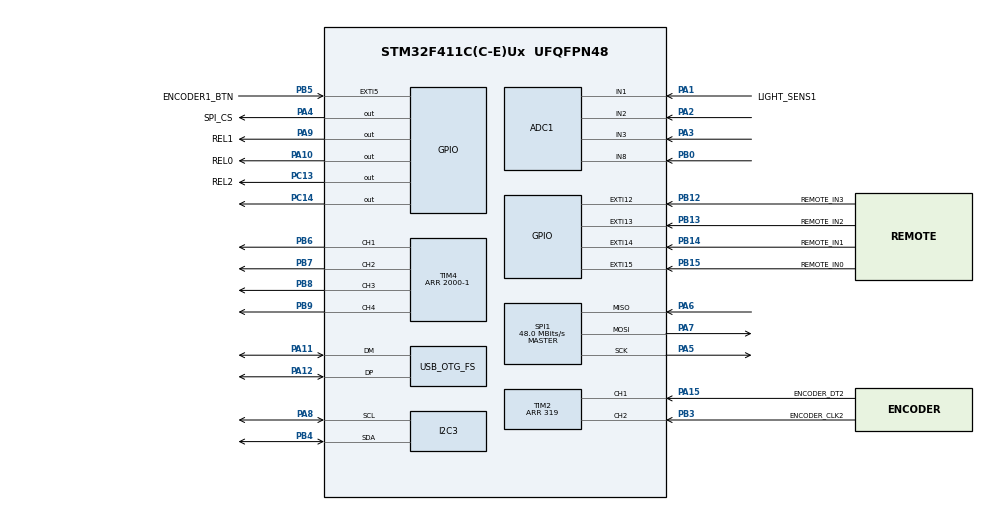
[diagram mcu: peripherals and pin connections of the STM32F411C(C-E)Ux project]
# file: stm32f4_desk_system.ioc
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ADC1.Channel-0\#ChannelRegularConversion=ADC_CHANNEL_1
ADC1.Channel-4\#ChannelRegularConversion=ADC_CHANNEL_2
ADC1.Channel-5\#ChannelRegularConversion=ADC_CHANNEL_3
ADC1.Channel-6\#ChannelRegularConversion=ADC_CHANNEL_8
ADC1.ClockPrescaler=ADC_CLOCK_SYNC_PCLK_DIV4
ADC1.ContinuousConvMode=ENABLE
ADC1.DMAContinuousRequests=ENABLE
ADC1.EOCSelection=ADC_EOC_SEQ_CONV
ADC1.NbrOfConversion=4
ADC1.NbrOfConversionFlag=1
ADC1.Rank-0\#ChannelRegularConversion=1
ADC1.Rank-4\#ChannelRegularConversion=2
ADC1.Rank-5\#ChannelRegularConversion=3
ADC1.Rank-6\#ChannelRegularConversion=4
ADC1.SamplingTime-0\#ChannelRegularConversion=ADC_SAMPLETIME_28CYCLES
ADC1.SamplingTime-4\#ChannelRegularConversion=ADC_SAMPLETIME_28CYCLES
ADC1.SamplingTime-5\#ChannelRegularConversion=ADC_SAMPLETIME_28CYCLES
ADC1.SamplingTime-6\#ChannelRegularConversion=ADC_SAMPLETIME_28CYCLES
ADC1.master=1
Dma.ADC1.0.Direction=DMA_PERIPH_TO_MEMORY
Dma.ADC1.0.FIFOMode=DMA_FIFOMODE_DISABLE
Dma.ADC1.0.Instance=DMA2_Stream0
Dma.ADC1.0.MemDataAlignment=DMA_MDATAALIGN_HALFWORD
Dma.ADC1.0.MemInc=DMA_MINC_ENABLE
Dma.ADC1.0.Mode=DMA_CIRCULAR
Dma.ADC1.0.PeriphDataAlignment=DMA_PDATAALIGN_HALFWORD
Dma.ADC1.0.PeriphInc=DMA_PINC_DISABLE
Dma.ADC1.0.Priority=DMA_PRIORITY_MEDIUM
Dma.Request0=ADC1
Mcu.Family=STM32F4
Mcu.Name=STM32F411C(C-E)Ux
Mcu.Package=UFQFPN48
NVIC.ADC_IRQn=true\:0\:0\:false\:false\:true\:true\:true
NVIC.DMA2_Stream0_IRQn=true\:0\:0\:false\:false\:true\:false\:true
NVIC.EXTI15_10_IRQn=true\:0\:0\:false\:false\:true\:true\:true
NVIC.EXTI9_5_IRQn=true\:0\:0\:false\:false\:true\:true\:true
NVIC.OTG_FS_IRQn=true\:0\:0\:false\:false\:true\:false\:true
NVIC.PriorityGroup=NVIC_PRIORITYGROUP_4
NVIC.TIM4_IRQn=true\:0\:0\:false\:false\:true\:true\:true
PA1.GPIO_Label=LIGHT_SENS1
PA1.Signal=ADCx_IN1
PA10.GPIO_Label=REL0
PA10.Signal=GPIO_Output
PA11.Mode=Device_Only
PA11.Signal=USB_OTG_FS_DM
PA12.Mode=Device_Only
PA12.Signal=USB_OTG_FS_DP
PA13.Mode=Serial_Wire
PA13.Signal=SYS_JTMS-SWDIO
PA14.Mode=Serial_Wire
PA14.Signal=SYS_JTCK-SWCLK
PA15.GPIO_Label=ENCODER_DT2
PA15.Signal=S_TIM2_CH1_ETR
PA2.Signal=ADCx_IN2
PA3.Signal=ADCx_IN3
PA4.GPIO_Label=SPI_CS
PA4.Signal=GPIO_Output
PA5.Mode=Full_Duplex_Master
PA5.Signal=SPI1_SCK
PA6.Mode=Full_Duplex_Master
PA6.Signal=SPI1_MISO
PA7.Mode=Full_Duplex_Master
PA7.Signal=SPI1_MOSI
PA8.Mode=I2C
PA8.Signal=I2C3_SCL
PA9.GPIO_Label=REL1
PA9.Signal=GPIO_Output
PB0.Signal=ADCx_IN8
PB12.GPIO_Label=REMOTE_IN3
PB12.GPIO_PuPd=GPIO_PULLDOWN
PB12.Signal=GPXTI12
PB13.GPIO_Label=REMOTE_IN2
PB13.GPIO_PuPd=GPIO_PULLDOWN
PB13.Signal=GPXTI13
PB14.GPIO_Label=REMOTE_IN1
PB14.GPIO_PuPd=GPIO_PULLDOWN
PB14.Signal=GPXTI14
PB15.GPIO_Label=REMOTE_IN0
PB15.GPIO_PuPd=GPIO_PULLDOWN
PB15.Signal=GPXTI15
PB3.GPIO_Label=ENCODER_CLK2
PB3.Signal=S_TIM2_CH2
PB4.Mode=I2C
PB4.Signal=I2C3_SDA
PB5.GPIO_Label=ENCODER1_BTN
PB5.GPIO_ModeDefaultEXTI=GPIO_MODE_IT_FALLING
PB5.Signal=GPXTI5
PB6.Signal=S_TIM4_CH1
PB7.Signal=S_TIM4_CH2
PB8.Signal=S_TIM4_CH3
PB9.Signal=S_TIM4_CH4
PC13-ANTI_TAMP.GPIO_Label=REL2
PC13-ANTI_TAMP.Signal=GPIO_Output
PC14-OSC32_IN.Signal=GPIO_Output
PH0\ -\ OSC_IN.Mode=HSE-External-Oscillator
PH0\ -\ OSC_IN.Signal=RCC_OSC_IN
PH1\ -\ OSC_OUT.Mode=HSE-External-Oscillator
PH1\ -\ OSC_OUT.Signal=RCC_OSC_OUT
ProjectManager.HeapSize=0x200
ProjectManager.StackSize=0x400
ProjectManager.TargetToolchain=STM32CubeIDE
RCC.48MHZClocksFreq_Value=48000000
RCC.AHBFreq_Value=96000000
RCC.APB1CLKDivider=RCC_HCLK_DIV2
RCC.APB1Freq_Value=48000000
RCC.APB1TimFreq_Value=96000000
RCC.APB2Freq_Value=96000000
RCC.APB2TimFreq_Value=96000000
RCC.CortexFreq_Value=96000000
RCC.HCLKFreq_Value=96000000
RCC.HSE_VALUE=25000000
RCC.HSI_VALUE=16000000
RCC.LSE_VALUE=32768
RCC.PLLM=25
RCC.SYSCLKFreq_VALUE=96000000
RCC.SYSCLKSource=RCC_SYSCLKSOURCE_PLLCLK
RCC.VCOOutputFreq_Value=192000000
SH.ADCx_IN1.0=ADC1_IN1,IN1
SH.ADCx_IN2.0=ADC1_IN2,IN2
SH.ADCx_IN3.0=ADC1_IN3,IN3
SH.ADCx_IN8.0=ADC1_IN8,IN8
SH.S_TIM2_CH1_ETR.0=TIM2_CH1,Encoder_Interface
SH.S_TIM2_CH2.0=TIM2_CH2,Encoder_Interface
SH.S_TIM4_CH1.0=TIM4_CH1,PWM Generation1 CH1
SH.S_TIM4_CH2.0=TIM4_CH2,PWM Generation2 CH2
SH.S_TIM4_CH3.0=TIM4_CH3,PWM Generation3 CH3
SH.S_TIM4_CH4.0=TIM4_CH4,PWM Generation4 CH4
SPI1.CalculateBaudRate=48.0 MBits/s
SPI1.Direction=SPI_DIRECTION_2LINES
SPI1.Mode=SPI_MODE_MASTER
SPI1.VirtualType=VM_MASTER
TIM2.CounterMode=TIM_COUNTERMODE_DOWN
TIM2.IC1Polarity=TIM_ICPOLARITY_FALLING
TIM2.IC2Polarity=TIM_ICPOLARITY_FALLING
TIM2.Period=319
TIM4.Channel-PWM\ Generation1\ CH1=TIM_CHANNEL_1
TIM4.Channel-PWM\ Generation2\ CH2=TIM_CHANNEL_2
TIM4.Channel-PWM\ Generation3\ CH3=TIM_CHANNEL_3
TIM4.Channel-PWM\ Generation4\ CH4=TIM_CHANNEL_4
TIM4.Period=2000-1
TIM9.Channel-Output\ Compare1\ No\ Output=TIM_CHANNEL_1
TIM9.Period=10000-1
TIM9.Prescaler=9
USB_DEVICE.CLASS_NAME_FS=CDC
USB_DEVICE.PRODUCT_STRING_CDC_FS=USB DESK SYSTEM
USB_DEVICE.VirtualMode=Cdc
USB_DEVICE.VirtualModeFS=Cdc_FS
USB_OTG_FS.VirtualMode=Device_Only
VP_TIM4_VS_ClockSourceINT.Mode=Internal
VP_TIM9_VS_ClockSourceINT.Mode=Internal
VP_TIM9_VS_no_output1.Mode=Output Compare1 No Output
VP_USB_DEVICE_VS_USB_DEVICE_CDC_FS.Mode=CDC_FS
board=custom

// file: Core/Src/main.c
/* USER CODE BEGIN Header */
/**
  ******************************************************************************
  * @file           : main.c
  * @brief          : Main program body
  ******************************************************************************
  * @attention
  *
  * <h2><center>&copy; Copyright (c) 2021 STMicroelectronics.
  * All rights reserved.</center></h2>
  *
  * This software component is licensed by ST under BSD 3-Clause license,
  * the "License"; You may not use this file except in compliance with the
  * License. You may obtain a copy of the License at:
  *                        opensource.org/licenses/BSD-3-Clause
  *
  ******************************************************************************
  */
/* USER CODE END Header */
#include "main.h"
#include "adc.h"
#include "dma.h"
#include "i2c.h"
#include "spi.h"
#include "tim.h"
#include "usb_device.h"
#include "gpio.h"

/* USER CODE BEGIN Includes */
#include "control.h"
#include "initialize.h"
#include "usbd_cdc_if.h"
#include "string.h"
//#include "OLED_SSD1306.h"
//#include "GFX_BW.h"
//#include "fonts/fonts.h"
//#include "picture.h"
/* USER CODE END Includes */

void SystemClock_Config(void);

/* USER CODE BEGIN 0 */

char *data= "hallo form microcontroller!\n";
uint8_t rec_buffer[512]={[0 ... 511] = 0};
/* USER CODE END 0 */

int main(void)
{

  /* MCU Configuration--------------------------------------------------------*/

  /* Reset of all peripherals, Initializes the Flash interface and the Systick. */
  HAL_Init();

  /* Configure the system clock */
  SystemClock_Config();

  /* Initialize all configured peripherals */
  MX_GPIO_Init();
  MX_TIM4_Init();
  MX_DMA_Init();
  MX_ADC1_Init();

  MX_TIM9_Init();
  MX_SPI1_Init();
  MX_TIM2_Init();
  MX_USB_DEVICE_Init();
  MX_I2C3_Init();
  /* USER CODE BEGIN 2 */

  hardware_initialize();
  /* USER CODE END 2 */

  /* Infinite loop */
  /* USER CODE BEGIN WHILE */
  while (1)
  {
	  //REMEMBER TO SWAP AUTO GENERATED BY CUBEMX FUNCTIONS CALLS TO ORDER: 1: dma INIT 2: adc1 init  (bug exists)
	  //WITHOUT THIS IT WONT WORK!!!!, DO IT AFTER EACH CODE GENERATION!
	  adc_vals_assign();
	  pwm_ctrl();
	  encoder_ctrl(&ENCODER1);
	  rel_ctrl(&REL0STAT);
	  rel_ctrl(&REL1STAT);
	  rel_ctrl(&REL2STAT);
//	  CDC_Transmit_FS((uint8_t *)data, strlen(data));
//	  LL_mDelay(1000);
	  //rysowanie ma sie odbywac tylko jak dma zakoczy trasfer poprzedniej ramki
//	  if(LL_DMA_IsActiveFlag_TC0(DMAx){
//	  if(Oled1.dmaFinished)
//	  {
//		  	SSD1306_Clear(BLACK,Oled1.frameBuffer);
//			GFX_DrawString(10,10, "21", WHITE, BLACK,Oled1.frameBuffer);
//
//			GFX_DrawString(10,20, "37", WHITE, BLACK,Oled1.frameBuffer);
//			GFX_DrawString(19,40, "www.msalamon.pl", WHITE, BLACK,Oled1.frameBuffer);
//	//		frames++;
//	//		HAL_GPIO_WritePin(TEST_GPIO_Port, TEST_Pin, 1);
//			SSD1306_Display();
//	  }

//  }

    /* USER CODE END WHILE */

  }
}

void SystemClock_Config(void)
{
  LL_FLASH_SetLatency(LL_FLASH_LATENCY_3);
  while(LL_FLASH_GetLatency()!= LL_FLASH_LATENCY_3)
  {
  }
  LL_PWR_SetRegulVoltageScaling(LL_PWR_REGU_VOLTAGE_SCALE1);
  LL_RCC_HSE_Enable();

   /* Wait till HSE is ready */
  while(LL_RCC_HSE_IsReady() != 1)
  {

  }
  LL_RCC_PLL_ConfigDomain_SYS(LL_RCC_PLLSOURCE_HSE, LL_RCC_PLLM_DIV_25, 192, LL_RCC_PLLP_DIV_2);
  LL_RCC_PLL_ConfigDomain_48M(LL_RCC_PLLSOURCE_HSE, LL_RCC_PLLM_DIV_25, 192, LL_RCC_PLLQ_DIV_4);
  LL_RCC_PLL_Enable();

   /* Wait till PLL is ready */
  while(LL_RCC_PLL_IsReady() != 1)
  {

  }
  LL_RCC_SetAHBPrescaler(LL_RCC_SYSCLK_DIV_1);
  LL_RCC_SetAPB1Prescaler(LL_RCC_APB1_DIV_2);
  LL_RCC_SetAPB2Prescaler(LL_RCC_APB2_DIV_1);
  LL_RCC_SetSysClkSource(LL_RCC_SYS_CLKSOURCE_PLL);

   /* Wait till System clock is ready */
  while(LL_RCC_GetSysClkSource() != LL_RCC_SYS_CLKSOURCE_STATUS_PLL)
  {

  }
  LL_SetSystemCoreClock(96000000);

   /* Update the time base */
  if (HAL_InitTick (TICK_INT_PRIORITY) != HAL_OK)
  {
    Error_Handler();
  }
  LL_RCC_SetTIMPrescaler(LL_RCC_TIM_PRESCALER_TWICE);
}

void Error_Handler(void)
{
  __disable_irq();
  while (1)
  {
  }
}

/************************ (C) COPYRIGHT STMicroelectronics *****END OF FILE****/
